# PIC32CM1216LS00100 device description
Architecture: CORTEX-M23; Family: PIC32CM; Series: PIC32CMLS00
Registers are 32-bit, read-write, reset 0x0 unless marked. A register's access mark holds for its fields unless they carry their own. Offsets are from the block's base; [hi:lo] are bit positions; lines under a group give offsets from that group; {n}, {i} and the like mark numbered series; 'fields as' and 'values as' point back to an identical list.

## OSC32KCTRL — 32k Oscillators Control
Instances: OSC32KCTRL 0x40001400
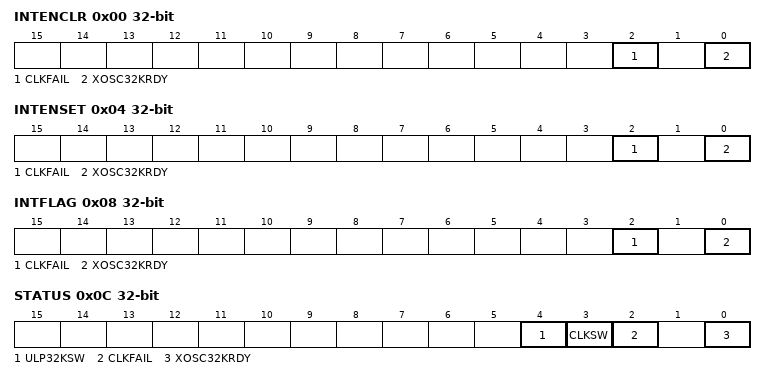
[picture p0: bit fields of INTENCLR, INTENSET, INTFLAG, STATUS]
0x00 INTENCLR (atomic clear) — Interrupt Enable Clear
  [2] CLKFAIL — XOSC32K Clock Failure Detector Interrupt Enable
  [0] XOSC32KRDY — XOSC32K Ready Interrupt Enable
0x04 INTENSET (atomic set) — Interrupt Enable Set
  fields as INTENCLR
0x08 INTFLAG (atomic clear) — Interrupt Flag Status and Clear
  [2] CLKFAIL — XOSC32K Clock Failure Detector
  [0] XOSC32KRDY — XOSC32K Ready
0x0C STATUS ro — Power and Clocks Status
  [4] ULP32KSW — OSCULP32K Clock Switch
  [3] CLKSW — XOSC32K Clock switch
  [2] CLKFAIL — XOSC32K Clock Failure Detector
  [0] XOSC32KRDY — XOSC32K Ready
0x10 RTCCTRL 8-bit — RTC Clock Selection
  [2:0] RTCSEL
    0=ULP1K (1.024kHz from 32kHz internal ULP oscillator); 1=ULP32K (32.768kHz from 32kHz internal ULP oscillator); 4=XOSC1K (1.024kHz from 32.768kHz external crystal oscillator); 5=XOSC32K (32.768kHz from 32.768kHz external crystal oscillator)
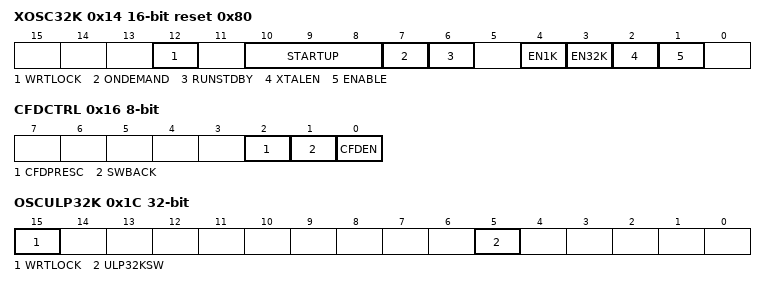
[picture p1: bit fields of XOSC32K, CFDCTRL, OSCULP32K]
0x14 XOSC32K 16-bit reset 0x80 — 32kHz External Crystal Oscillator (XOSC32K) Control
  [12] WRTLOCK — Write Lock
  [10:8] STARTUP — Oscillator Start-Up Time
    0=CYCLE2048 (62.5 ms); 1=CYCLE4096 (125 ms); 2=CYCLE16384 (500 ms); 3=CYCLE32768 (1000 ms); 4=CYCLE65536 (2000 ms); 5=CYCLE131072 (4000 ms); 6=CYCLE262144 (8000 ms)
  [7] ONDEMAND — On Demand Control
  [6] RUNSTDBY — Run in Standby
  [4] EN1K — 1kHz Output Enable
  [3] EN32K — 32kHz Output Enable
  [2] XTALEN — Crystal Oscillator Enable
  [1] ENABLE — Oscillator Enable
0x16 CFDCTRL 8-bit — Clock Failure Detector Control
  [2] CFDPRESC — Clock Failure Detector Prescaler
  [1] SWBACK — Clock Switch Back Enable
  [0] CFDEN — Clock Failure Detector Enable
0x17 EVCTRL 8-bit — Event Control
  [0] CFDEO — Clock Failure Detector Event Output Enable
0x1C OSCULP32K — 32kHz Ultra Low Power Internal Oscillator (OSCULP32K) Control
  [15] WRTLOCK — Write Lock
  [5] ULP32KSW — OSCULP32K Clock Switch Enable

## PM — Power Manager
Instances: PM 0x40000400
0x01 SLEEPCFG 8-bit reset 0x2 — Sleep Configuration
  [2:0] SLEEPMODE
    2=IDLE (CPU, AHBx, and APBx clocks are OFF); 4=STANDBY (ALL clocks are OFF, unless requested by sleepwalking peripheral); 6=OFF (All power domains are powered OFF)
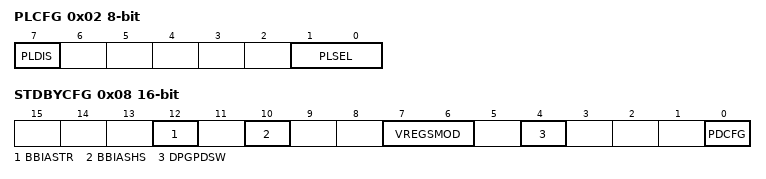
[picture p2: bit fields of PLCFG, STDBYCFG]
0x02 PLCFG 8-bit — Performance Level Configuration
  [7] PLDIS — Performance Level Disable
  [1:0] PLSEL — Performance Level Select
    0=PL0 (Performance Level 0); 2=PL2 (Performance Level 2)
0x03 PWCFG 8-bit — Power Configuration
  [1:0] RAMPSWC — RAM Power Switch Configuration
    0=64KB (64KB Available); 1=48KB (48KB Available); 2=32KB (32KB Available); 3=16KB (16KB Available)
0x04 INTENCLR 8-bit (atomic clear) — Interrupt Enable Clear
  [0] PLRDY — Performance Level Interrupt Enable
0x05 INTENSET 8-bit (atomic set) — Interrupt Enable Set
  [0] PLRDY — Performance Level Ready interrupt Enable
0x06 INTFLAG 8-bit (atomic clear) — Interrupt Flag Status and Clear
  [0] PLRDY — Performance Level Ready
0x08 STDBYCFG 16-bit — Standby Configuration
  [12] BBIASTR — Back Bias for Trust RAM
  [10] BBIASHS — Back Bias for SRAM
  [7:6] VREGSMOD — Voltage Regulator Standby mode
    0=AUTO (Automatic mode); 1=PERFORMANCE (Performance oriented); 2=LP (Low Power oriented)
  [4] DPGPDSW — Dynamic Power Gating for PDSW
    0=DISABLED (Dynamic Power Gating disabled); 1=ENABLED (Dynamic Power Gating enabled)
  [0] PDCFG — Power Domain Configuration
    0=DEFAULT (PDSW power domain switching is handled by hardware.); 1=PDSW (PDSW is forced ACTIVE.)

## PORT — Port Module
Instances: PORT 0x40003000, PORT_SEC 0x40003200, PORT_IOBUS 0x60000000, PORT_IOBUS_SEC 0x60000200
{0x0+0x80*i} GROUP[{i}] (i=0..2) group
  0x00 DIR — Data Direction
    [31:0] DIR — Port Data Direction
  0x04 DIRCLR (atomic clear of DIR) — Data Direction Clear
    [31:0] DIRCLR — Port Data Direction Clear
  0x08 DIRSET (atomic set of DIR) — Data Direction Set
    [31:0] DIRSET — Port Data Direction Set
  0x0C DIRTGL (atomic toggle of DIR) — Data Direction Toggle
    [31:0] DIRTGL — Port Data Direction Toggle
  0x10 OUT — Data Output Value
    [31:0] OUT — PORT Data Output Value
  0x14 OUTCLR (atomic clear of OUT) — Data Output Value Clear
    [31:0] OUTCLR — PORT Data Output Value Clear
  0x18 OUTSET (atomic set of OUT) — Data Output Value Set
    [31:0] OUTSET — PORT Data Output Value Set
  0x1C OUTTGL (atomic toggle of OUT) — Data Output Value Toggle
    [31:0] OUTTGL — PORT Data Output Value Toggle
  0x20 IN ro — Data Input Value
    [31:0] IN — PORT Data Input Value
  0x24 CTRL — Control
    [31:0] SAMPLING — Input Sampling Mode
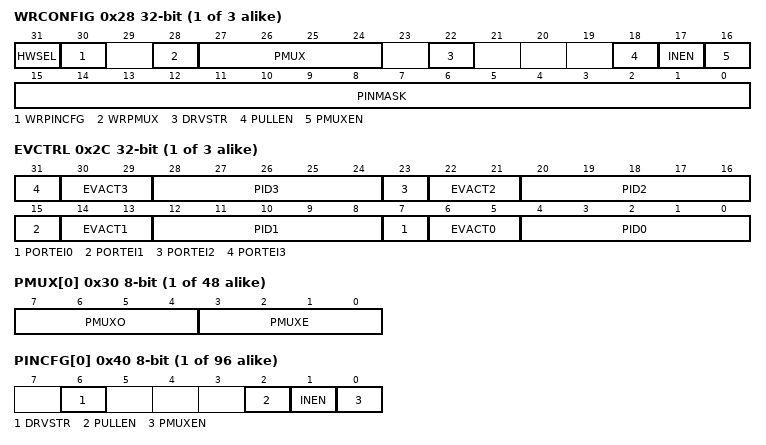
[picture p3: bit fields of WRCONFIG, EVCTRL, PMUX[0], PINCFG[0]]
  0x28 WRCONFIG wo — Write Configuration
    [31] HWSEL — Half-Word Select
    [30] WRPINCFG — Write PINCFG
    [28] WRPMUX — Write PMUX
    [27:24] PMUX — Peripheral Multiplexing
    [22] DRVSTR — Output Driver Strength Selection
    [18] PULLEN — Pull Enable
    [17] INEN — Input Enable
    [16] PMUXEN — Peripheral Multiplexer Enable
    [15:0] PINMASK — Pin Mask for Multiple Pin Configuration
  0x2C EVCTRL — Event Input Control
    [8n+7] PORTEI{n} (n=0..3) — PORT Event Input Enable {n}
    [30:29] EVACT3 — PORT Event Action 3
    [8n+4:8n] PID{n} (n=0..3) — PORT Event Pin Identifier {n}
    [22:21] EVACT2 — PORT Event Action 2
    [14:13] EVACT1 — PORT Event Action 1
    [6:5] EVACT0 — PORT Event Action 0
      0=OUT (Event output to pin); 1=SET (Set output register of pin on event); 2=CLR (Clear output register of pin on event); 3=TGL (Toggle output register of pin on event)
  {0x30+j} PMUX[{j}] (j=0..15) 8-bit — Peripheral Multiplexing
    [7:4] PMUXO — Peripheral Multiplexing for Odd-Numbered Pin
      0=A (Peripheral function A selected); 1=B (Peripheral function B selected); 2=C (Peripheral function C selected); 3=D (Peripheral function D selected); 4=E (Peripheral function E selected); 6=G (Peripheral function G selected); 7=H (Peripheral function H selected); 8=I (Peripheral function I selected); 9=J (Peripheral function J selected); 10=K (Peripheral function K selected)
    [3:0] PMUXE — Peripheral Multiplexing for Even-Numbered Pin
      values as PMUXO
  {0x40+j} PINCFG[{j}] (j=0..31) 8-bit — Pin Configuration
    [6] DRVSTR — Output Driver Strength Selection
    [2] PULLEN — Pull Enable
    [1] INEN — Input Enable
    [0] PMUXEN — Peripheral Multiplexer Enable
  0x60 INTENCLR (atomic clear) — Interrupt Enable Clear
    [0] NSCHK — Non-Secure Check Interrupt Enable
  0x64 INTENSET (atomic set) — Interrupt Enable Set
    [0] NSCHK — Non-Secure Check Interrupt Enable
  0x68 INTFLAG (atomic clear) — Interrupt Flag Status and Clear
    [0] NSCHK — Non-Secure Check
  0x6C NONSEC — Security Attribution
    [31:0] NONSEC — Port Security Attribution
  0x70 NSCHK — Security Attribution Check
    [31:0] NSCHK — Port Security Attribution Check

## Notices in the file
Copyright (c) 2019 Microchip Technology Inc.
SPDX-License-Identifier: Apache-2.0
Licensed under the Apache License, Version 2.0 (the "License");
you may not use this file except in compliance with the License.
You may obtain a copy of the License at
http://www.apache.org/licenses/LICENSE-2.0
Unless required by applicable law or agreed to in writing, software
distributed under the License is distributed on an "AS IS" BASIS,
WITHOUT WARRANTIES OR CONDITIONS OF ANY KIND, either express or implied.
See the License for the specific language governing permissions and
limitations under the License.
